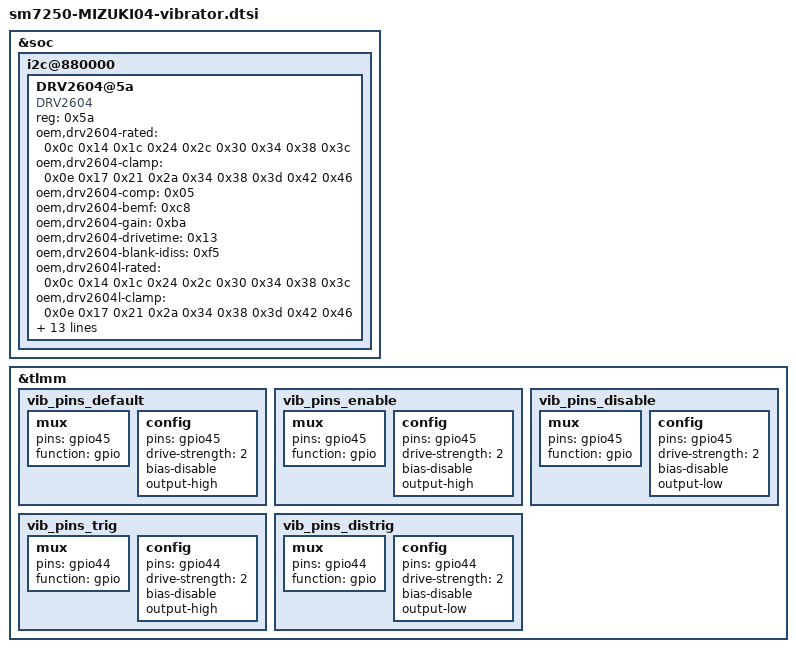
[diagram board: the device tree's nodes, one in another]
/*
 * This software is contributed or developed by KYOCERA Corporation.
 * (C) 2020 KYOCERA Corporation
 * (C) 2021 KYOCERA Corporation
 *
 * This program is free software; you can redistribute it and/or modify
 * it under the terms of the GNU General Public License version 2 and
 * only version 2 as published by the Free Software Foundation.
 *
 * This program is distributed in the hope that it will be useful,
 * but WITHOUT ANY WARRANTY; without even the implied warranty of
 * MERCHANTABILITY or FITNESS FOR A PARTICULAR PURPOSE.  See the
 * GNU General Public License for more details.
 */

&soc {
	i2c@880000 {
		DRV2604@5a {
			compatible = "DRV2604";
			reg = <0x5a>;
			oem,drv2604-rated = <0x0c 0x14 0x1c 0x24 0x2c 0x30 0x34 0x38 0x3c>;
			oem,drv2604-clamp = <0x0e 0x17 0x21 0x2a 0x34 0x38 0x3d 0x42 0x46>;
			oem,drv2604-comp = <0x05>;
			oem,drv2604-bemf = <0xc8>;
			oem,drv2604-gain = <0xba>;
			oem,drv2604-drivetime = <0x13>;
			oem,drv2604-blank-idiss = <0xf5>;
			oem,drv2604l-rated = <0x0c 0x14 0x1c 0x24 0x2c 0x30 0x34 0x38 0x3c>;
			oem,drv2604l-clamp = <0x0e 0x17 0x21 0x2a 0x34 0x38 0x3d 0x42 0x46>;
			oem,drv2604l-comp = <0x05>;
			oem,drv2604l-bemf = <0xc8>;
			oem,drv2604l-gain = <0xba>;
			oem,drv2604l-drivetime = <0x13>;
			oem,drv2604l-blank-idiss = <0xf5>;
			oem,drv2604l-ext-blank-idiss = <0x00>;
			oem,vib-en-gpio = <&tlmm 45 0x00>;
			oem,vib-intrig-gpio = <&tlmm 44 0x00>;
			pinctrl-names = "default", "vib_enable_pin", "vib_disable_pin",
				"vib_trig_pin", "vib_distrig_pin";
			pinctrl-0 = <&vib_pins_default>;
			pinctrl-1 = <&vib_pins_enable>;
			pinctrl-2 = <&vib_pins_disable>;
			pinctrl-3 = <&vib_pins_trig>;
			pinctrl-4 = <&vib_pins_distrig>;
		};
	};
};

&tlmm {
	vib_pins_default: vib_pins_default {
		mux {
			pins = "gpio45";
			function = "gpio";
		};
		config {
			pins = "gpio45";
			drive-strength = <2>;
			bias-disable;
			output-high;
		};
	};

	vib_pins_enable: vib_pins_enable {
		mux {
			pins = "gpio45";
			function = "gpio";
		};
		config {
			pins = "gpio45";
			drive-strength = <2>;
			bias-disable;
			output-high;
		};
	};

	vib_pins_disable: vib_pins_disable {
		mux {
			pins = "gpio45";
			function = "gpio";
		};
		config {
			pins = "gpio45";
			drive-strength = <2>;
			bias-disable;
			output-low;
		};
	};

	vib_pins_trig: vib_pins_trig {
		mux {
			pins = "gpio44";
			function = "gpio";
		};
		config {
			pins = "gpio44";
			drive-strength = <2>;
			bias-disable;
			output-high;
		};
	};

	vib_pins_distrig: vib_pins_distrig {
		mux {
			pins = "gpio44";
			function = "gpio";
		};
		config {
			pins = "gpio44";
			drive-strength = <2>;
			bias-disable;
			output-low;
		};
	};
};
